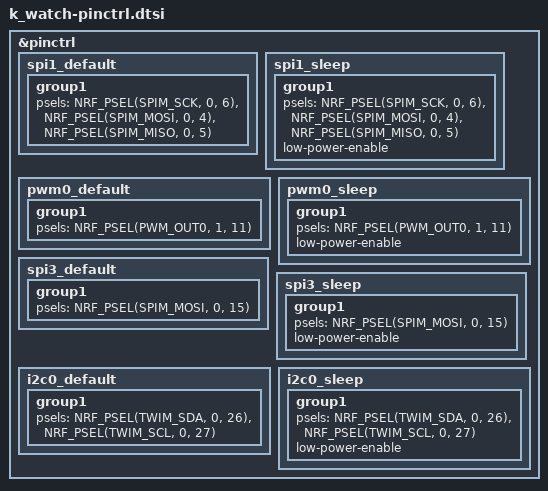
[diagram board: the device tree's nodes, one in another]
&pinctrl {
	spi1_default: spi1_default {
		group1 {
			psels = <NRF_PSEL(SPIM_SCK, 0, 6)>,
				<NRF_PSEL(SPIM_MOSI, 0, 4)>,
				<NRF_PSEL(SPIM_MISO, 0, 5)>;
		};
	};

	spi1_sleep: spi1_sleep {
		group1 {
			psels = <NRF_PSEL(SPIM_SCK, 0, 6)>,
				<NRF_PSEL(SPIM_MOSI, 0, 4)>,
				<NRF_PSEL(SPIM_MISO, 0, 5)>;
			low-power-enable;
		};
	};

	pwm0_default: pwm0_default {
		group1 {
			psels = <NRF_PSEL(PWM_OUT0, 1, 11)>;
		};
	};

	pwm0_sleep: pwm0_sleep {
		group1 {
			psels = <NRF_PSEL(PWM_OUT0, 1, 11)>;
			low-power-enable;
		};
	};

	spi3_default: spi3_default {
		group1 {
			psels = <NRF_PSEL(SPIM_MOSI, 0, 15)>;
		};
	};

	spi3_sleep: spi3_sleep {
		group1 {
			psels = <NRF_PSEL(SPIM_MOSI, 0, 15)>;
			low-power-enable;
		};
	};

	i2c0_default: i2c0_default {
		group1 {
			psels = <NRF_PSEL(TWIM_SDA, 0, 26)>,
				<NRF_PSEL(TWIM_SCL, 0, 27)>;
		};
	};

	i2c0_sleep: i2c0_sleep {
		group1 {
			psels = <NRF_PSEL(TWIM_SDA, 0, 26)>,
				<NRF_PSEL(TWIM_SCL, 0, 27)>;
			low-power-enable;
		};
	};
};
